# ETHSW register map
Registers are 32-bit, read-only, no defined reset value unless marked. A register's access mark holds for its fields unless they carry their own. Addresses are absolute; registers are grouped by the start of their names; [hi:lo] are bit positions; {n}, {i} and the like mark numbered series.

## PTPClockIdentity1
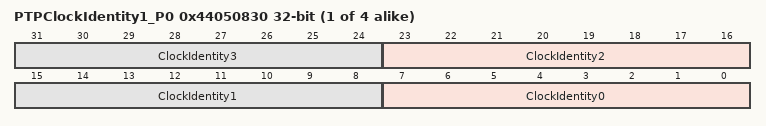
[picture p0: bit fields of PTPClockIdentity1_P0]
{0x44050830+0x400*i} PTPClockIdentity1_P{i} access not given (i=0..3)
  [8n+7:8n] ClockIdentity{n} (n=0..3)

## PTPClockIdentity2
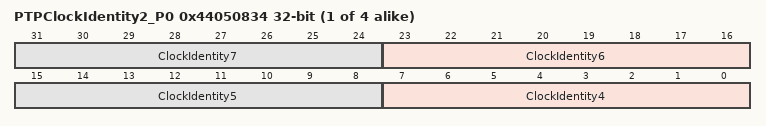
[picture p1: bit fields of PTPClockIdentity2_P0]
{0x44050834+0x400*i} PTPClockIdentity2_P{i} access not given (i=0..3)
  [8n-25:8n-32] ClockIdentity{n} (n=4..7)

## PTPAutoResponse
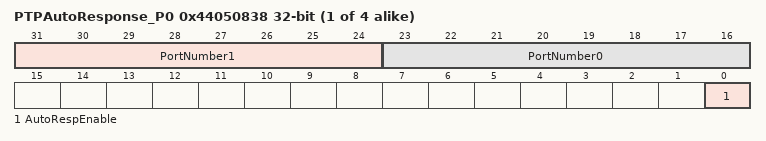
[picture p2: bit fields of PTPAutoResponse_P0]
{0x44050838+0x400*i} PTPAutoResponse_P{i} access not given (i=0..3)
  [31:24] PortNumber1, [23:16] PortNumber0, [0] AutoRespEnable

## STATUS
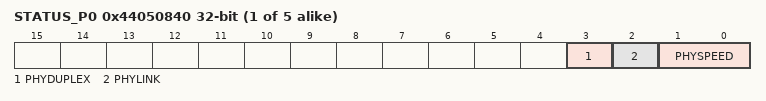
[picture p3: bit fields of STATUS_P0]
{0x44050840+0x400*i} STATUS_P{i} (i=0..4)
  [3] PHYDUPLEX, [2] PHYLINK, [1:0] PHYSPEED

## TX
{0x44050844+0x400*i} TX_IPG_LENGTH_P{i} access not given (i=0..4)
  [4:0] TX_IPG_LENGTH
0x44053C68 TX_STAT0
0x44053C78 TX_STAT1

## EEE
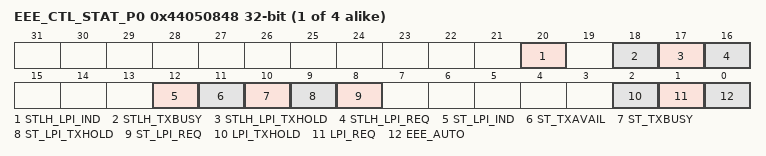
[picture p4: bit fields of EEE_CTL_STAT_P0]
{0x44050848+0x400*i} EEE_CTL_STAT_P{i} (i=0..3)
  [20] STLH_LPI_IND, [18] STLH_TXBUSY, [17] STLH_LPI_TXHOLD, [16] STLH_LPI_REQ, [12] ST_LPI_IND, [11] ST_TXAVAIL, [10] ST_TXBUSY, [9] ST_LPI_TXHOLD, [8] ST_LPI_REQ, [2] LPI_TXHOLD, [1] LPI_REQ, [0] EEE_AUTO
{0x4405084C+0x400*i} EEE_IDLE_TIME_P{i} access not given (i=0..3)
{0x44050850+0x400*i} EEE_TWSYS_TIME_P{i} access not given (i=0..3)

## IDLE
{0x44050854+0x400*i} IDLE_SLOPE_P{i} access not given (i=0..4)
  [10:0] IDLE_SLOPE

## aFramesTransmittedOK
{0x44050868+0x400*i} aFramesTransmittedOK_P{i} (i=0..4)

## aFramesReceivedOK
{0x4405086C+0x400*i} aFramesReceivedOK_P{i} (i=0..4)

## aFrameCheckSequenceErrors
{0x44050870+0x400*i} aFrameCheckSequenceErrors_P{i} (i=0..4)

## aAlignmentErrors
{0x44050874+0x400*i} aAlignmentErrors_P{i} (i=0..4)

## aOctetsTransmittedOK
{0x44050878+0x400*i} aOctetsTransmittedOK_P{i} (i=0..4)

## aOctetsReceivedOK
{0x4405087C+0x400*i} aOctetsReceivedOK_P{i} (i=0..4)

## aTxPAUSEMACCtrlFrames
{0x44050880+0x400*i} aTxPAUSEMACCtrlFrames_P{i} (i=0..4)

## aRxPAUSEMACCtrlFrames
{0x44050884+0x400*i} aRxPAUSEMACCtrlFrames_P{i} (i=0..4)

## ifInErrors
{0x44050888+0x400*i} ifInErrors_P{i} (i=0..4)

## ifOutErrors
{0x4405088C+0x400*i} ifOutErrors_P{i} (i=0..4)

## ifInUcastPkts
{0x44050890+0x400*i} ifInUcastPkts_P{i} (i=0..4)

## ifInMulticastPkts
{0x44050894+0x400*i} ifInMulticastPkts_P{i} (i=0..4)

## ifInBroadcastPkts
{0x44050898+0x400*i} ifInBroadcastPkts_P{i} (i=0..4)

## ifOutDiscards
{0x4405089C+0x400*i} ifOutDiscards_P{i} (i=0..4)

## ifOutUcastPkts
{0x440508A0+0x400*i} ifOutUcastPkts_P{i} (i=0..4)

## ifOutMulticastPkts
{0x440508A4+0x400*i} ifOutMulticastPkts_P{i} (i=0..4)

## ifOutBroadcastPkts
{0x440508A8+0x400*i} ifOutBroadcastPkts_P{i} (i=0..4)

## etherStatsDropEvents
{0x440508AC+0x400*i} etherStatsDropEvents_P{i} (i=0..4)

## etherStatsOctets
{0x440508B0+0x400*i} etherStatsOctets_P{i} (i=0..4)

## etherStatsPkts
{0x440508B4+0x400*i} etherStatsPkts_P{i} (i=0..4)

## etherStatsUndersizePkts
{0x440508B8+0x400*i} etherStatsUndersizePkts_P{i} (i=0..4)
